# S32R372 register map
Vendor: Freescale Semiconductor, Inc.; Series: Qorivva; File version: 1.6
Registers are 32-bit, read-write, reset 0x0 unless marked. A register's access mark holds for its fields unless they carry their own. Offsets are from the block's base; [hi:lo] are bit positions; {n}, {i} and the like mark numbered series; 'fields as' and 'values as' point back to an identical list.

## ETIMER_1 — eTimer
Base 0xFFC24000; register names take the prefix ETIMER_1_
{0x0+0x20*i} CH{i}_COMP1 (i=0..7) 16-bit — Channel n Compare Register 1
  [15:0] COMP1 — Value used for comparison with the counter value
{0x2+0x20*i} CH{i}_COMP2 (i=0..7) 16-bit — Channel n Compare Register 2
  [15:0] COMP2 — Value used for comparison with the counter value
{0x4+0x20*i} CH{i}_CAPT1 (i=0..7) 16-bit ro — Channel n Capture Register 1
  [15:0] CAPT1 — Value captured from the counter
{0x6+0x20*i} CH{i}_CAPT2 (i=0..7) 16-bit ro — Channel n Capture Register 2
  [15:0] CAPT2 — Value captured from the counter
{0x8+0x20*i} CH{i}_LOAD (i=0..7) 16-bit — Channel n Load Register
  [15:0] LOAD — Value used to initialize the counter
{0xA+0x20*i} CH{i}_HOLD (i=0..7) 16-bit ro — Channel n Hold Register
  [15:0] HOLD — Stores the counter's value whenever any of the counters within a module are read.
{0xC+0x20*i} CH{i}_CNTR (i=0..7) 16-bit — Channel n Counter Register
  [15:0] CNTR — Counter for this channel of the timer module
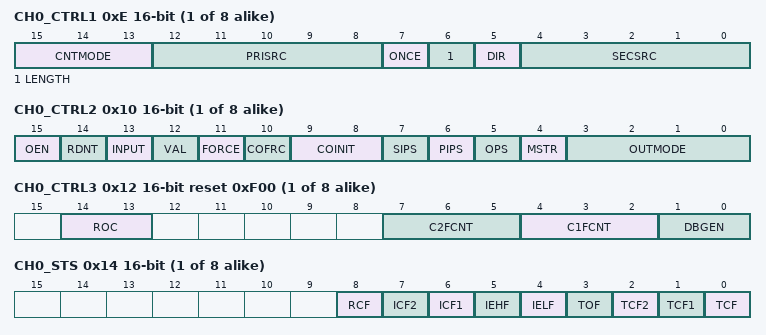
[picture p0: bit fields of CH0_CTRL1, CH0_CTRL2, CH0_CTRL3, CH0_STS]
{0xE+0x20*i} CH{i}_CTRL1 (i=0..7) 16-bit — Channel n Control Register 1
  [15:13] CNTMODE — Count mode
    0=No Operation; 1=Count rising edges of primary source (Rising edges counted only when PIPS = 0. Falling edges counted when PIPS = 1. If primary count source is IP bus clock, only rising edges are counted regardless of PIPS value.); 2=Count rising and falling edges of primary source (IP Bus clock divide by 1 can not be used as a primary count source in edge count mode.); 3=Count rising edges of primary source while secondary input high active; 4=Quadrature count mode, uses primary and secondary sources; 5=Count primary source rising edges, secondary source specifies direction (1 = minus) (Rising edges counted only when PIPS = 0. Falling edges counted when PIPS = 1.); 6=Edge of secondary source triggers primary count till compare; 7=Cascaded counter mode, up/down (Primary count source must be set to one of the counter outputs.)
  [12:8] PRISRC — Primary Count Source
    {v}=Counter #{v} input pin (v=0..7); {v}=Auxiliary input #{v-8} pin (v=8..15); {v}=Counter #{v-16} output (v=16..21); 22=Counter #6 output pin; 23=Counter #7 output pin; 24=IP Bus clock divide by 1 prescaler; 25=IP Bus clock divide by 2 prescaler; 26=IP Bus clock divide by 4 prescaler; 27=IP Bus clock divide by 8 prescaler; 28=IP Bus clock divide by 16 prescaler; 29=IP Bus clock divide by 32 prescaler; 30=IP Bus clock divide by 64 prescaler; 31=IP Bus clock divide by 128 prescaler
  [7] ONCE — Count once
    0=Count repeatedly; 1=Count until compare and then stop. When output mode 4h is used, the counter re-initializes after reaching the COMP1 value and continues to count to the COMP2 value then stops.
  [6] LENGTH — Count Length
    0=Continue counting to roll over; 1=Count until compare, then reinitialize. The value that the counter is reinitialized with depends on the settings of CLC1 and CLC2. If neither of these indicates the counter is to be loaded from one of the CMPLD registers, then the LOAD register is used to reinitialize the counter upon matching either COMP register. If one of CLC1 or CLC2 indicates that the counter is to be loaded from one of the CMPLD registers, then the counter will reinitialize to the value in the appropriate CMPLD register upon a match with the appropriate COMP register. If both of the CLC1 and CLC2 fields indicate that the counter is to be loaded from the CMPLD registers, then CMPLD1 will have priority if both compares happen at the same value. When output mode 4h is used, alternating values of COMP1 and COMP2 are used to generate successful comparisons. For example, the counter counts until COMP1 value is reached, re-initializes, then counts until COMP2 value is reached, re-initializes, then counts until COMP1 value is reached, etc.
  [5] DIR — Count Direction
    0=Count up; 1=Count down
  [4:0] SECSRC — Secondary Count Source
    {v}=Counter #{v} input pin (v=0..7); {v}=Auxiliary input #{v-8} pin (v=8..15); {v}=Counter #{v-16} output (v=16..21); 22=Counter #6 output pin; 23=Counter #7 output pin
{0x10+0x20*i} CH{i}_CTRL2 (i=0..7) 16-bit — Channel n Control Register 2
  [15] OEN — Output Enable
    0=The external pin is configured as an input; 1=OFLAG output signal will be driven on the external pin. Other timer channels using this external pin as their input will see the driven value. The polarity of the signal will be determined by the OPS bit.
  [14] RDNT — Redundant Channel Enable
    0=Disable redundant channel checking; 1=Enable redundant channel checking
  [13] INPUT ro — External input signal
  [12] VAL — Forced OFLAG Value
  [11] FORCE wo — Force the OFLAG output
  [10] COFRC — Co-channel OFLAG Force
    0=Other channels cannot force the OFLAG of this channel; 1=Other channels may force the OFLAG of this channel
  [9:8] COINIT — Co-channel Initialization
    1=Other channels may force a re-initialization of this channel's counter using the LOAD reg; 2=Other channels may force a re-initialization of this channel's counter with the CMPLD2 reg when this channel is counting down or the CMPLD1 reg when this channel is counting up
  [7] SIPS — Secondary Source Input Polarity Select
    0=True polarity; 1=Inverted polarity
  [6] PIPS — Primary Source Input Polarity Select
    0=True polarity; 1=Inverted polarity
  [5] OPS — Output Polarity Select.
    0=True polarity; 1=Inverted polarity
  [4] MSTR — Master Mode
    0=Disable broadcast of compare events from this channel; 1=Enable broadcast of compare events from this channel
  [3:0] OUTMODE — Output Mode
    0=Software controlled; 1=Clear OFLAG output on successful compare (COMP1 or COMP2); 2=Set OFLAG output on successful compare (COMP1 or COMP2); 3=Toggle OFLAG output on successful compare (COMP1 or COMP2); 4=Toggle OFLAG output using alternating compare registers; 5=Set on compare with COMP1, cleared on secondary source input edge; 6=Set on compare with COMP2, cleared on secondary source input edge; 7=Set on compare, cleared on counter roll-over; 8=Set on successful compare on COMP1, clear on successful compare on COMP2; 9=Asserted while counter is active, cleared when counter is stopped; 10=Asserted when counting up, cleared when counting down; 15=Enable gated clock output while counter is active
{0x12+0x20*i} CH{i}_CTRL3 (i=0..7) 16-bit reset 0xF00 — Channel n Control Register 3
  [14:13] ROC — Reload on Capture
    0=Do not reload the counter on a capture event; 1=Reload the counter on a capture 1 event; 2=Reload the counter on a capture 2 event; 3=Reload the counter on both a capture 1 event and a capture 2 event
  [7:5] C2FCNT ro — Capture 2 FIFO count
  [4:2] C1FCNT ro — Capture 1 FIFO count
  [1:0] DBGEN — Debug Actions Enable
    0=Continue with normal operation during debug mode. (default); 1=Halt channel counter during debug mode; 2=Force OFLAG to logic 0 (prior to consideration of the OPS bit) during debug mode; 3=Both halt counter and force OFLAG to 0 during debug mode
{0x14+0x20*i} CH{i}_STS (i=0..7) 16-bit — Channel n Status Register
  [8] RCF — Redundant Channel Flag
  [7] ICF2 — Input Capture 2 Flag
  [6] ICF1 — Input Capture 1 Flag
  [5] IEHF — Input Edge High Flag
  [4] IELF — Input Edge Low Flag
  [3] TOF — Timer Overflow Flag
  [2] TCF2 — Timer Compare 2 Flag
  [1] TCF1 — Timer Compare 1 Flag
  [0] TCF — This bit is set when a successful compare occurs
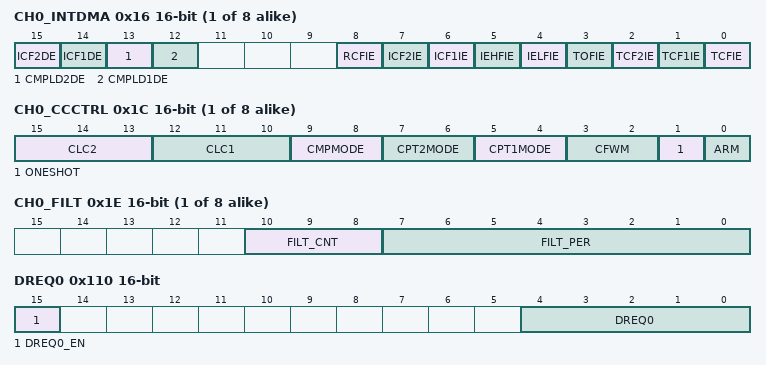
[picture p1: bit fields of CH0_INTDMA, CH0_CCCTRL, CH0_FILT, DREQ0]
{0x16+0x20*i} CH{i}_INTDMA (i=0..7) 16-bit — Channel n Interrupt and DMA Enable Register
  [15] ICF2DE — Input Capture 2 Flag DMA Enable
  [14] ICF1DE — Input Capture 1 Flag DMA Enable
  [13] CMPLD2DE — Comparator Load Register 2 Flag DMA Enable
  [12] CMPLD1DE — Comparator Load Register 1 Flag DMA Enable
  [8] RCFIE — Redundant Channel Flag Interrupt Enable
  [7] ICF2IE — Input Capture 2 Flag Interrupt Enable
  [6] ICF1IE — Input Capture 1 Flag Interrupt Enable
  [5] IEHFIE — Input Edge High Flag Interrupt Enable
  [4] IELFIE — Input Edge Low Flag Interrupt Enable
  [3] TOFIE — Timer Overflow Flag Interrupt Enable
  [2] TCF2IE — Timer Compare 2 Flag Interrupt Enable
  [1] TCF1IE — Timer Compare 1 Flag Interrupt Enable
  [0] TCFIE — Timer Compare Flag Interrupt Enable
{0x18+0x20*i} CH{i}_CMPLD1 (i=0..7) 16-bit — Channel n Comparator Load Register 1
  [15:0] CMPLD1 — Preload value for the COMP1 register
{0x1A+0x20*i} CH{i}_CMPLD2 (i=0..7) 16-bit — Channel n Comparator Load Register 2
  [15:0] CMPLD2 — Preload value for the COMP2 register
{0x1C+0x20*i} CH{i}_CCCTRL (i=0..7) 16-bit — Channel n Compare and Capture Control Register
  [15:13] CLC2 — Compare Load Control 2
    0=Never preload; 2=Load COMP2 with CMPLD1 upon successful compare with the value in COMP1; 3=Load COMP2 with CMPLD1 upon successful compare with the value in COMP2; 4=Load COMP2 with CMPLD2 upon successful compare with the value in COMP1; 5=Load COMP2 with CMPLD2 upon successful compare with the value in COMP2; 6=Load CNTR with CMPLD2 upon successful compare with the value in COMP1; 7=Load CNTR with CMPLD2 upon successful compare with the value in COMP2
  [12:10] CLC1 — Compare Load Control 1
    0=Never preload; 2=Load COMP1 with CMPLD1 upon successful compare with the value in COMP1; 3=Load COMP1 with CMPLD1 upon successful compare with the value in COMP2; 4=Load COMP1 with CMPLD2 upon successful compare with the value in COMP1; 5=Load COMP1 with CMPLD2 upon successful compare with the value in COMP2; 6=Load CNTR with CMPLD1 upon successful compare with the value in COMP1; 7=Load CNTR with CMPLD1 upon successful compare with the value in COMP2
  [9:8] CMPMODE — Compare Mode
    0=COMP1 register is used when the counter is counting up; COMP2 register is used when the counter is counting up; 1=COMP1 register is used when the counter is counting down; COMP2 register is used when the counter is counting up; 2=COMP1 register is used when the counter is counting up. COMP2 register is used when the counter is counting down.; 3=COMP1 register is used when the counter is counting down; COMP2 register is used when the counter is counting down
  [7:6] CPT2MODE — Capture 2 Mode Control
    0=Disabled; 1=Capture falling edges; 2=Capture rising edges; 3=Capture any edge
  [5:4] CPT1MODE — Capture 1 Mode Control
    values as CPT2MODE
  [3:2] CFWM — Capture FIFO Water Mark
  [1] ONESHOT — One Shot Capture Mode
    0=Free running mode is selected. If both capture circuits are enabled, then capture circuit 1 is armed first after the ARM bit is set. Once a capture occurs, capture circuit 1 is disarmed and capture circuit 2 is armed. After capture circuit 2 performs a capture, it is disarmed and capture circuit 1 is re-armed. The process continues indefinitely. If only one of the capture circuits is enabled, then captures continue indefinitely on the enabled capture circuit.; 1=One shot mode is selected. If both capture circuits are enabled, then capture circuit 1 is armed first after the ARM bit is set. Once a capture occurs, capture circuit 1 is disarmed and capture circuit 2 is armed. After capture circuit 2 performs a capture, it is disarmed and the ARM bit is cleared. No further captures will be performed until the ARM bit is set again. If only one of the capture circuits is enabled, then a single capture will occur on the enabled capture circuit and the ARM bit is then cleared.
  [0] ARM — Arm Capture
    0=Input capture operation is disabled; 1=Input capture operation as specified by the CPT1MODE and CPT2MODE bits is enabled
{0x1E+0x20*i} CH{i}_FILT (i=0..7) 16-bit — Channel n Input Filter Register
  [10:8] FILT_CNT — Input Filter Sample Count
  [7:0] FILT_PER — Input Filter Sample Period
0x10C ENBL 16-bit reset 0xFF — Channel Enable Register
  [7:0] ENBL — Timer Channel Enable
    0=Timer channel is disabled; 1=Timer channel is enabled. This is the reset value.
0x110 DREQ0 16-bit — DMA Request 0 Select Register
  [15] DREQ0_EN — DMA Request Enable Use this bit to enable the module-level DMA request output
    0=DMA request disabled; 1=DMA request enabled
  [4:0] DREQ0 — DMA Request Select Use this field to select which DMA request source will be muxed onto one of the four module level DMA request outputs
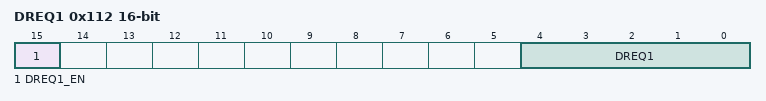
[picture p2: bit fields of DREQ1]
0x112 DREQ1 16-bit — DMA Request 1 Select Register
  [15] DREQ1_EN — DMA Request Enable Use this bit to enable the module-level DMA request output
    0=DMA request disabled; 1=DMA request enabled
  [4:0] DREQ1 — DMA Request Select
